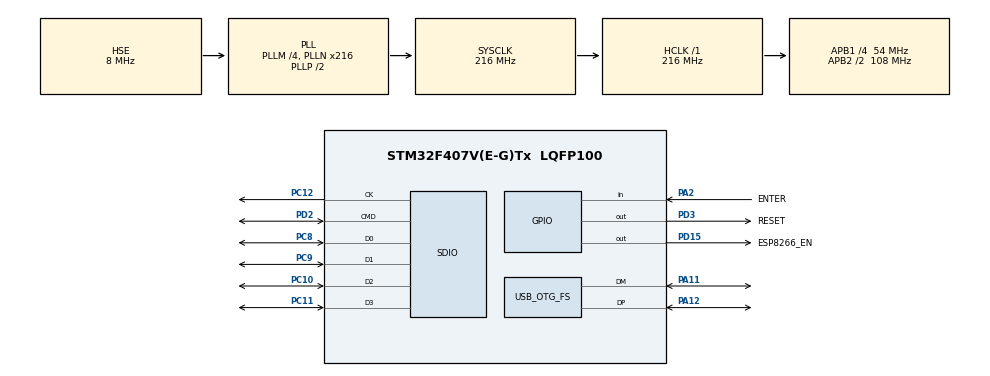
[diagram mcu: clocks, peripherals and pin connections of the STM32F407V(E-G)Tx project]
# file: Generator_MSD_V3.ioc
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Mcu.Family=STM32F4
Mcu.Name=STM32F407V(E-G)Tx
Mcu.Package=LQFP100
NVIC.OTG_FS_IRQn=true\:0\:0\:false\:false\:true\:false\:true
NVIC.PriorityGroup=NVIC_PRIORITYGROUP_4
PA11.Mode=Device_Only
PA11.Signal=USB_OTG_FS_DM
PA12.Mode=Device_Only
PA12.Signal=USB_OTG_FS_DP
PA13.Mode=Serial_Wire
PA13.Signal=SYS_JTMS-SWDIO
PA14.Mode=Serial_Wire
PA14.Signal=SYS_JTCK-SWCLK
PA2.GPIO_Label=ENTER
PA2.Signal=GPIO_Input
PC10.Mode=SD_4_bits_Wide_bus
PC10.Signal=SDIO_D2
PC11.Mode=SD_4_bits_Wide_bus
PC11.Signal=SDIO_D3
PC12.Mode=SD_4_bits_Wide_bus
PC12.Signal=SDIO_CK
PC8.Mode=SD_4_bits_Wide_bus
PC8.Signal=SDIO_D0
PC9.Mode=SD_4_bits_Wide_bus
PC9.Signal=SDIO_D1
PD15.GPIO_Label=ESP8266_EN
PD15.Signal=GPIO_Output
PD2.Mode=SD_4_bits_Wide_bus
PD2.Signal=SDIO_CMD
PD3.GPIO_Label=RESET
PD3.GPIO_PuPd=GPIO_PULLUP
PD3.PinState=GPIO_PIN_SET
PD3.Signal=GPIO_Output
PH0-OSC_IN.Mode=HSE-External-Oscillator
PH0-OSC_IN.Signal=RCC_OSC_IN
PH1-OSC_OUT.Mode=HSE-External-Oscillator
PH1-OSC_OUT.Signal=RCC_OSC_OUT
ProjectManager.HeapSize=0x4000
ProjectManager.StackSize=0x4000
ProjectManager.TargetToolchain=STM32CubeIDE
RCC.48MHZClocksFreq_Value=48000000
RCC.AHBFreq_Value=216000000
RCC.APB1CLKDivider=RCC_HCLK_DIV4
RCC.APB1Freq_Value=54000000
RCC.APB1TimFreq_Value=108000000
RCC.APB2CLKDivider=RCC_HCLK_DIV2
RCC.APB2Freq_Value=108000000
RCC.APB2TimFreq_Value=216000000
RCC.CortexFreq_Value=216000000
RCC.HCLKFreq_Value=216000000
RCC.HSE_VALUE=8000000
RCC.HSI_VALUE=16000000
RCC.LSE_VALUE=32768
RCC.PLLM=4
RCC.PLLN=216
RCC.PLLQ=9
RCC.SYSCLKFreq_VALUE=216000000
RCC.SYSCLKSource=RCC_SYSCLKSOURCE_PLLCLK
RCC.VCOOutputFreq_Value=432000000
SDIO.ClockBypass=SDIO_CLOCK_BYPASS_DISABLE
SDIO.ClockDiv=2
SDIO.ClockPowerSave=SDIO_CLOCK_POWER_SAVE_ENABLE
SDIO.HardwareFlowControl=SDIO_HARDWARE_FLOW_CONTROL_ENABLE
USB_DEVICE.CLASS_NAME_FS=MSC
USB_DEVICE.MSC_MEDIA_PACKET-MSC_FS=16384
USB_DEVICE.VirtualMode-MSC_FS=Msc
USB_DEVICE.VirtualModeFS=Msc_FS
USB_OTG_FS.VirtualMode=Device_Only
VP_USB_DEVICE_VS_USB_DEVICE_MSC_FS.Mode=MSC_FS
board=custom

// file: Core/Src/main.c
/* USER CODE BEGIN Header */
/**
  ******************************************************************************
  * @file           : main.c
  * @brief          : Main program body
  ******************************************************************************
  * @attention
  *
  * <h2><center>&copy; Copyright (c) 2021 STMicroelectronics.
  * All rights reserved.</center></h2>
  *
  * This software component is licensed by ST under Ultimate Liberty license
  * SLA0044, the "License"; You may not use this file except in compliance with
  * the License. You may obtain a copy of the License at:
  *                             www.st.com/SLA0044
  *
  ******************************************************************************
  */
/* USER CODE END Header */
#include "main.h"
#include "sdio.h"
#include "usb_device.h"
#include "gpio.h"

void SystemClock_Config(void);

int main(void)
{
  /* USER CODE BEGIN 1 */
	__disable_irq(); //????????? ??????????
	SCB->VTOR = 0x8004000;
	__enable_irq(); //????????? ??????????
  /* USER CODE END 1 */

  /* MCU Configuration--------------------------------------------------------*/

  /* Reset of all peripherals, Initializes the Flash interface and the Systick. */
  HAL_Init();

  /* Configure the system clock */
  SystemClock_Config();

  /* USER CODE BEGIN SysInit */
  SPI1->CR1 =0;
  ADC1->CR1 = 0;
  ADC1->CR2 = 0;

  /* USER CODE END SysInit */

  /* Initialize all configured peripherals */
  MX_GPIO_Init();
  MX_USB_DEVICE_Init();
  MX_SDIO_SD_Init();

  /* Infinite loop */
  while (1)
  {

  }
}

void SystemClock_Config(void)
{
  RCC_OscInitTypeDef RCC_OscInitStruct = {0};
  RCC_ClkInitTypeDef RCC_ClkInitStruct = {0};

  /** Configure the main internal regulator output voltage
  */
  __HAL_RCC_PWR_CLK_ENABLE();
  __HAL_PWR_VOLTAGESCALING_CONFIG(PWR_REGULATOR_VOLTAGE_SCALE1);
  /** Initializes the RCC Oscillators according to the specified parameters
  * in the RCC_OscInitTypeDef structure.
  */
  RCC_OscInitStruct.OscillatorType = RCC_OSCILLATORTYPE_HSE;
  RCC_OscInitStruct.HSEState = RCC_HSE_ON;
  RCC_OscInitStruct.PLL.PLLState = RCC_PLL_ON;
  RCC_OscInitStruct.PLL.PLLSource = RCC_PLLSOURCE_HSE;
  RCC_OscInitStruct.PLL.PLLM = 4;
  RCC_OscInitStruct.PLL.PLLN = 216;
  RCC_OscInitStruct.PLL.PLLP = RCC_PLLP_DIV2;
  RCC_OscInitStruct.PLL.PLLQ = 9;
  if (HAL_RCC_OscConfig(&RCC_OscInitStruct) != HAL_OK)
  {
    Error_Handler();
  }
  /** Initializes the CPU, AHB and APB buses clocks
  */
  RCC_ClkInitStruct.ClockType = RCC_CLOCKTYPE_HCLK|RCC_CLOCKTYPE_SYSCLK
                              |RCC_CLOCKTYPE_PCLK1|RCC_CLOCKTYPE_PCLK2;
  RCC_ClkInitStruct.SYSCLKSource = RCC_SYSCLKSOURCE_PLLCLK;
  RCC_ClkInitStruct.AHBCLKDivider = RCC_SYSCLK_DIV1;
  RCC_ClkInitStruct.APB1CLKDivider = RCC_HCLK_DIV4;
  RCC_ClkInitStruct.APB2CLKDivider = RCC_HCLK_DIV2;

  if (HAL_RCC_ClockConfig(&RCC_ClkInitStruct, FLASH_LATENCY_5) != HAL_OK)
  {
    Error_Handler();
  }
}

void Error_Handler(void)
{
  __disable_irq();
  while (1)
  {
  }
}

/************************ (C) COPYRIGHT STMicroelectronics *****END OF FILE****/
